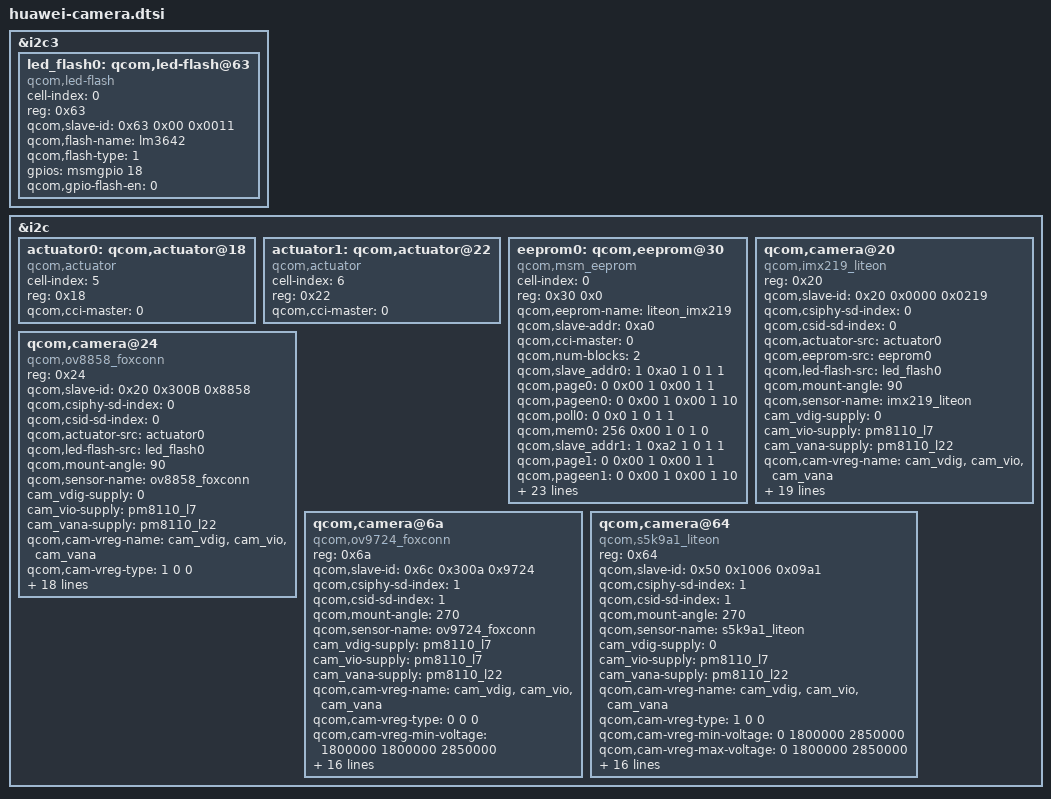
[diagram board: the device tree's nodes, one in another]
/*
 * Copyright (c) 2012-2013, The Linux Foundation. All rights reserved.
 *
 * This program is free software; you can redistribute it and/or modify
 * it under the terms of the GNU General Public License version 2 and
 * only version 2 as published by the Free Software Foundation.
 *
 * This program is distributed in the hope that it will be useful,
 * but WITHOUT ANY WARRANTY; without even the implied warranty of
 * MERCHANTABILITY or FITNESS FOR A PARTICULAR PURPOSE.  See the
 * GNU General Public License for more details.
 */
&i2c3 {
       led_flash0: qcom,led-flash@63 {
		cell-index = <0>;
		reg = <0x63>;
		qcom,slave-id = <0x63 0x00 0x0011>;
		compatible = "qcom,led-flash";
		qcom,flash-name = "lm3642";
		qcom,flash-type = <1>;
		gpios = <&msmgpio 18 0>;
		qcom,gpio-flash-en = <0>;
       };
};

&i2c {
	actuator0: qcom,actuator@18 {
		cell-index = <5>;
		reg = <0x18>;
		compatible = "qcom,actuator";
		qcom,cci-master = <0>;
	};
	actuator1: qcom,actuator@22 {
		cell-index = <6>;
		reg = <0x22>;
		compatible = "qcom,actuator";
		qcom,cci-master = <0>;
	};
	eeprom0: qcom,eeprom@30 {
			cell-index = <0>;
			reg = <0x30 0x0>; //a fake addr for register, mclk src already defined 6-0030.
			qcom,eeprom-name = "liteon_imx219";
			compatible = "qcom,msm_eeprom";
			qcom,slave-addr = <0xa0>;
			qcom,cci-master = <0>;
			qcom,num-blocks = <2>;
			qcom,slave_addr0 = <1 0xa0 1 0 1 1>;
			qcom,page0 = <0 0x00 1 0x00 1 1>;
			qcom,pageen0 = <0 0x00 1 0x00 1 10>;
			qcom,poll0 = <0 0x0 1 0 1 1>;
			qcom,mem0 = <256 0x00 1 0 1 0>;

			qcom,slave_addr1 = <1 0xa2 1 0 1 1>;
			qcom,page1 = <0 0x00 1 0x00 1 1>;
			qcom,pageen1 = <0 0x00 1 0x00 1 10>;
			qcom,poll1 = <0 0x0 1 0 1 1>;
			qcom,mem1 = <40 0x00 1 0 1 0>;

			cam_vdig-supply = <0>;
			cam_vio-supply = <&pm8110_l7>;
			cam_vana-supply = <&pm8110_l22>;
			qcom,cam-vreg-name = "cam_vdig", "cam_vio", "cam_vana";
			qcom,cam-vreg-type = <1 0 0>;
			qcom,cam-vreg-min-voltage = <0 1800000 2850000>;
			qcom,cam-vreg-max-voltage = <0 1800000 2850000>;
			qcom,cam-vreg-op-mode = <0 200000 100000>;
			qcom,gpio-no-mux = <0>;
			gpios = <&msmgpio 13 0>,
				<&msmgpio 21 0>;//reset
			qcom,gpio-reset = <1>;
			qcom,gpio-req-tbl-num = <0 1>;
			qcom,gpio-req-tbl-flags = <1 0>;
			qcom,gpio-req-tbl-label = "CAMIF_MCLK",
					"CAM_RESET";
			qcom,cam-power-seq-type = "sensor_vreg",
					"sensor_vreg", "sensor_gpio",
					"sensor_clk";
			qcom,cam-power-seq-val = "cam_vio", "cam_vana",
					"sensor_gpio_reset",
					"sensor_cam_mclk" ;
			qcom,cam-power-seq-cfg-val = <1 1 1 24000000>;
			qcom,cam-power-seq-delay = <1 1 10 5>;
		};
	qcom,camera@20 {
		compatible = "qcom,imx219_liteon";
		reg = <0x20>;
		qcom,slave-id = <0x20 0x0000 0x0219>;
		qcom,csiphy-sd-index = <0>;
		qcom,csid-sd-index = <0>;
		qcom,actuator-src = <&actuator0>;
		qcom,eeprom-src = <&eeprom0>;
		qcom,led-flash-src = <&led_flash0>;
		qcom,mount-angle = <90>;
		qcom,sensor-name = "imx219_liteon";
		cam_vdig-supply = <0>;
		cam_vio-supply = <&pm8110_l7>;
		cam_vana-supply = <&pm8110_l22>;
		qcom,cam-vreg-name = "cam_vdig", "cam_vio", "cam_vana";
		qcom,cam-vreg-type = <1 0 0>;
		qcom,cam-vreg-min-voltage = <0 1800000 2850000>;
		qcom,cam-vreg-max-voltage = <0 1800000 2850000>;
		qcom,cam-vreg-op-mode = <0 200000 100000>;
		qcom,gpio-no-mux = <0>;
		gpios = <&msmgpio 13 0>,
			<&msmgpio 21 0>,
			<&msmgpio 94 0>,
			<&msmgpio 101 0>;
		qcom,gpio-reset = <1>;
		qcom,gpio-vdig = <3>;
		qcom,gpio-af-pwdm = <2>;
		qcom,gpio-req-tbl-num = <0 1 2 3>;
		qcom,gpio-req-tbl-flags = <1 0 0 0>;
		qcom,gpio-req-tbl-label = "CAMIF_MCLK",
			"CAM_RESET",
			"CAM_VCMPWDN",
			"CAM_DVDDEN";
		qcom,csi-lane-assign = <0xe4>;
		qcom,csi-lane-mask = <0x7>;
		qcom,sensor-position = <0>;
		qcom,sensor-mode = <1>;
		qcom,cci-master = <0>;
	};

	qcom,camera@24 {
		compatible = "qcom,ov8858_foxconn";
		reg = <0x24>;
		qcom,slave-id = <0x20 0x300B 0x8858>;
		qcom,csiphy-sd-index = <0>;
		qcom,csid-sd-index = <0>;
		qcom,actuator-src = <&actuator0>;
		qcom,led-flash-src = <&led_flash0>;
		qcom,mount-angle = <90>;
		qcom,sensor-name = "ov8858_foxconn";
		cam_vdig-supply = <0>;
		cam_vio-supply = <&pm8110_l7>;
		cam_vana-supply = <&pm8110_l22>;
		qcom,cam-vreg-name = "cam_vdig", "cam_vio", "cam_vana";
		qcom,cam-vreg-type = <1 0 0>;
		qcom,cam-vreg-min-voltage = <0 1800000 2850000>;
		qcom,cam-vreg-max-voltage = <0 1800000 2850000>;
		qcom,cam-vreg-op-mode = <0 200000 100000>;
		qcom,gpio-no-mux = <0>;
		gpios = <&msmgpio 13 0>,
			<&msmgpio 21 0>,
			<&msmgpio 94 0>,
			<&msmgpio 101 0>;
		qcom,gpio-reset = <1>;
		qcom,gpio-vdig = <3>;
		qcom,gpio-af-pwdm = <2>;
		qcom,gpio-req-tbl-num = <0 1 2 3>;
		qcom,gpio-req-tbl-flags = <1 0 0 0>;
		qcom,gpio-req-tbl-label = "CAMIF_MCLK",
			"CAM_RESET",
			"CAM_VCMPWDN",
			"CAM_DVDDEN";
		qcom,csi-lane-assign = <0xe4>;
		qcom,csi-lane-mask = <0x7>;
		qcom,sensor-position = <0>;
		qcom,sensor-mode = <1>;
		qcom,cci-master = <0>;
	};

	qcom,camera@6a {
		compatible = "qcom,ov9724_foxconn";
		reg = <0x6a>;
		qcom,slave-id = <0x6c 0x300a 0x9724>;
		qcom,csiphy-sd-index = <1>;
		qcom,csid-sd-index = <1>;
		qcom,mount-angle = <270>;
		qcom,sensor-name = "ov9724_foxconn";
		cam_vdig-supply = <&pm8110_l7>;
		cam_vio-supply = <&pm8110_l7>;
		cam_vana-supply = <&pm8110_l22>;
		qcom,cam-vreg-name = "cam_vdig", "cam_vio", "cam_vana";
		qcom,cam-vreg-type = <0 0 0>;
		qcom,cam-vreg-min-voltage = <1800000 1800000 2850000>;
		qcom,cam-vreg-max-voltage = <1800000 1800000 2850000>;
		qcom,cam-vreg-op-mode = <200000 200000 100000>;
		qcom,gpio-no-mux = <0>;
		gpios = <&msmgpio 13 0>,
			<&msmgpio 15 0>,
			<&msmgpio 85 0>;
		qcom,gpio-reset = <1>;
		qcom,gpio-standby = <2>;
		qcom,gpio-req-tbl-num = <0 1 2>;
		qcom,gpio-req-tbl-flags = <1 0 0>;
		qcom,gpio-req-tbl-label = "CAMIF_MCLK",
			"CAM_RESET",
			"CAM_STANDBY";
		qcom,csi-lane-assign = <0xe4>;
		qcom,csi-lane-mask = <0x3>;
		qcom,sensor-position = <1>;
		qcom,sensor-mode = <1>;
		qcom,cci-master = <0>;
	};

	qcom,camera@64 {
		compatible = "qcom,s5k9a1_liteon";
		reg = <0x64>;
		qcom,slave-id = <0x50 0x1006 0x09a1>;
		qcom,csiphy-sd-index = <1>;
		qcom,csid-sd-index = <1>;
		qcom,mount-angle = <270>;
		qcom,sensor-name = "s5k9a1_liteon";
		cam_vdig-supply = <0>;
		cam_vio-supply = <&pm8110_l7>;
		cam_vana-supply = <&pm8110_l22>;
		qcom,cam-vreg-name = "cam_vdig", "cam_vio", "cam_vana";
		/*s5k9a1 dvdd don't use ldo7, it use gpio101 control 1.2v*/
		qcom,cam-vreg-type = <1 0 0>;
		qcom,cam-vreg-min-voltage = <0 1800000 2850000>;
		qcom,cam-vreg-max-voltage = <0 1800000 2850000>;
		qcom,cam-vreg-op-mode = <0 200000 100000>;
		qcom,gpio-no-mux = <0>;
		gpios = <&msmgpio 13 0>,
			<&msmgpio 15 0>,
			<&msmgpio 85 0>,
			<&msmgpio 101 0>;
		qcom,gpio-reset = <1>;
		qcom,gpio-standby = <2>;
		qcom,gpio-vdig = <3>;
		qcom,gpio-req-tbl-num = <0 1 2 3>;
		qcom,gpio-req-tbl-flags = <1 0 0 0>;
		qcom,gpio-req-tbl-label = "CAMIF_MCLK",
			"CAM_RESET",
			"CAM_STANDBY",
			"CAM_DVDDEN";
		qcom,csi-lane-assign = <0xe4>;
		qcom,csi-lane-mask = <0x3>;
		qcom,sensor-position = <1>;
		qcom,sensor-mode = <1>;
		qcom,cci-master = <0>;
	};
};
